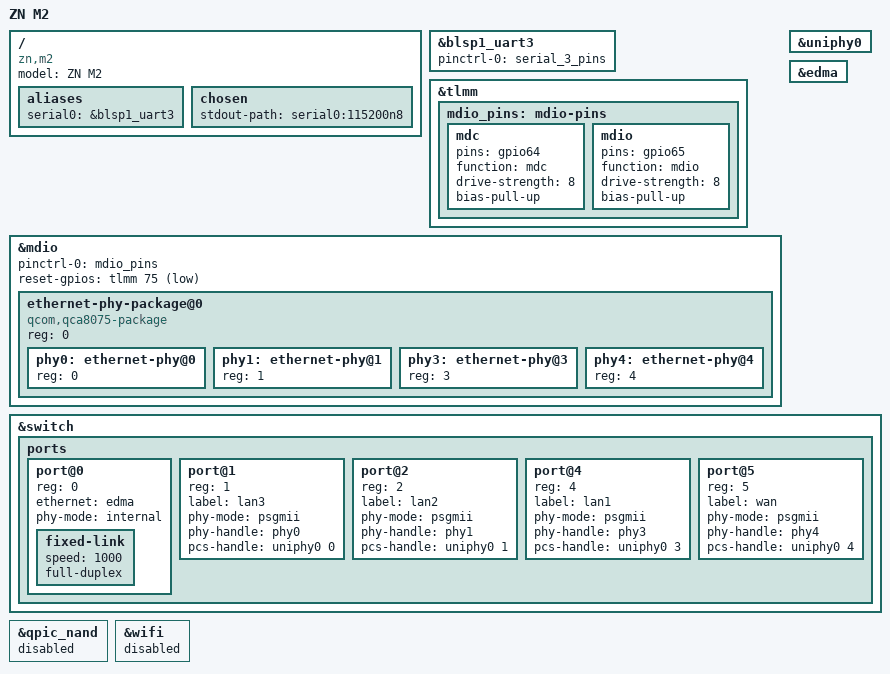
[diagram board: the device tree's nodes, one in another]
// SPDX-License-Identifier: GPL-2.0-or-later OR MIT
/dts-v1/;
#include "ipq6018.dtsi"
#include "ipq6018-ess.dtsi"
#include "ipq6018-cp-cpu.dtsi"
#include "ipq6018-512m.dtsi"
#include <dt-bindings/gpio/gpio.h>

/ {
	model = "ZN M2";
	compatible = "zn,m2", "qcom,ipq6018";
	aliases { serial0 = &blsp1_uart3; };
	chosen { stdout-path = "serial0:115200n8"; };
};

&blsp1_uart3 {
	pinctrl-0 = <&serial_3_pins>;
	pinctrl-names = "default";
	status = "okay";
};

&tlmm {
	mdio_pins: mdio-pins {
		mdc { pins = "gpio64"; function = "mdc"; drive-strength = <8>; bias-pull-up; };
		mdio { pins = "gpio65"; function = "mdio"; drive-strength = <8>; bias-pull-up; };
	};
};

&mdio {
	status = "okay";
	pinctrl-0 = <&mdio_pins>;
	pinctrl-names = "default";
	reset-gpios = <&tlmm 75 GPIO_ACTIVE_LOW>;
	ethernet-phy-package@0 {
		compatible = "qcom,qca8075-package";
		#address-cells = <1>;
		#size-cells = <0>;
		reg = <0>;
		phy0: ethernet-phy@0 { reg = <0>; };
		phy1: ethernet-phy@1 { reg = <1>; };
		phy3: ethernet-phy@3 { reg = <3>; };
		phy4: ethernet-phy@4 { reg = <4>; };
	};
};

&uniphy0 { status = "okay"; };
&edma { status = "okay"; };
&switch {
	status = "okay";
	ports {
		#address-cells = <1>;
		#size-cells = <0>;
		port@0 {
			reg = <0>;
			ethernet = <&edma>;
			phy-mode = "internal";
			fixed-link { speed = <1000>; full-duplex; };
		};
		port@1 { reg = <1>; label = "lan3"; phy-mode = "psgmii"; phy-handle = <&phy0>; pcs-handle = <&uniphy0 0>; };
		port@2 { reg = <2>; label = "lan2"; phy-mode = "psgmii"; phy-handle = <&phy1>; pcs-handle = <&uniphy0 1>; };
		port@4 { reg = <4>; label = "lan1"; phy-mode = "psgmii"; phy-handle = <&phy3>; pcs-handle = <&uniphy0 3>; };
		port@5 { reg = <5>; label = "wan"; phy-mode = "psgmii"; phy-handle = <&phy4>; pcs-handle = <&uniphy0 4>; };
	};
};

&qpic_nand { status = "disabled"; };
&wifi { status = "disabled"; };
